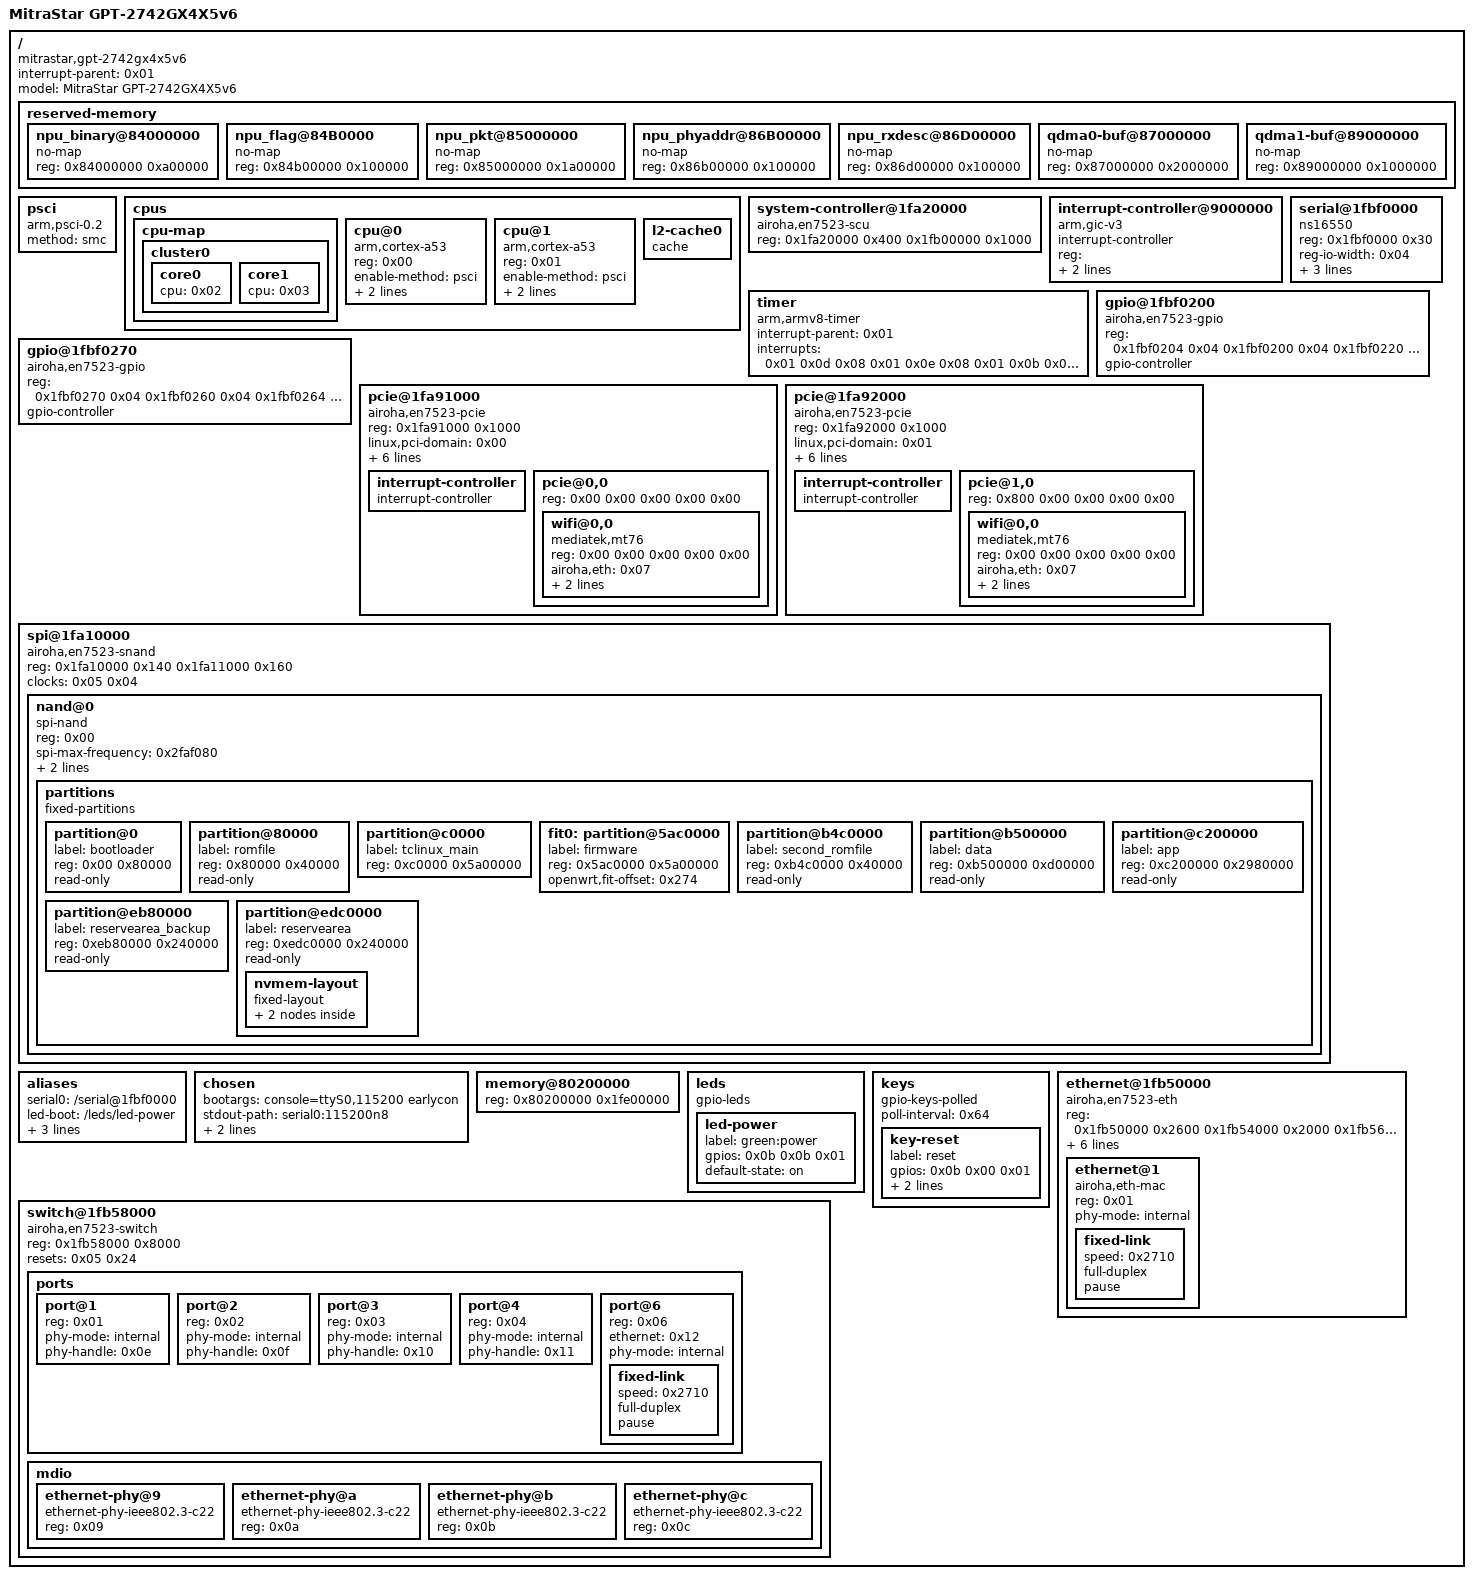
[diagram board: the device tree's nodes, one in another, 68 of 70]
/dts-v1/;

/memreserve/	0x0000000080000000 0x0000000000200000;
/ {
	interrupt-parent = <0x01>;
	#address-cells = <0x01>;
	#size-cells = <0x01>;
	model = "MitraStar GPT-2742GX4X5v6";
	compatible = "mitrastar,gpt-2742gx4x5v6\0airoha,en7523";

	reserved-memory {
		#address-cells = <0x01>;
		#size-cells = <0x01>;
		ranges;

		npu_binary@84000000 {
			no-map;
			reg = <0x84000000 0xa00000>;
		};

		npu_flag@84B0000 {
			no-map;
			reg = <0x84b00000 0x100000>;
		};

		npu_pkt@85000000 {
			no-map;
			reg = <0x85000000 0x1a00000>;
		};

		npu_phyaddr@86B00000 {
			no-map;
			reg = <0x86b00000 0x100000>;
		};

		npu_rxdesc@86D00000 {
			no-map;
			reg = <0x86d00000 0x100000>;
		};

		qdma0-buf@87000000 {
			no-map;
			reg = <0x87000000 0x2000000>;
			phandle = <0x0c>;
		};

		qdma1-buf@89000000 {
			no-map;
			reg = <0x89000000 0x1000000>;
			phandle = <0x0d>;
		};
	};

	psci {
		compatible = "arm,psci-0.2";
		method = "smc";
	};

	cpus {
		#address-cells = <0x01>;
		#size-cells = <0x00>;

		cpu-map {

			cluster0 {

				core0 {
					cpu = <0x02>;
				};

				core1 {
					cpu = <0x03>;
				};
			};
		};

		cpu@0 {
			device_type = "cpu";
			compatible = "arm,cortex-a53";
			reg = <0x00>;
			enable-method = "psci";
			clock-frequency = <0x4c4b400>;
			next-level-cache = <0x04>;
			phandle = <0x02>;
		};

		cpu@1 {
			device_type = "cpu";
			compatible = "arm,cortex-a53";
			reg = <0x01>;
			enable-method = "psci";
			clock-frequency = <0x4c4b400>;
			next-level-cache = <0x04>;
			phandle = <0x03>;
		};

		l2-cache0 {
			compatible = "cache";
			phandle = <0x04>;
		};
	};

	system-controller@1fa20000 {
		compatible = "airoha,en7523-scu";
		reg = <0x1fa20000 0x400 0x1fb00000 0x1000>;
		#clock-cells = <0x01>;
		#reset-cells = <0x01>;
		phandle = <0x05>;
	};

	interrupt-controller@9000000 {
		compatible = "arm,gic-v3";
		interrupt-controller;
		#interrupt-cells = <0x03>;
		#address-cells = <0x01>;
		#size-cells = <0x01>;
		reg = <0x9000000 0x20000 0x9080000 0x80000 0x9400000 0x2000 0x9500000 0x2000 0x9600000 0x20000>;
		interrupts = <0x01 0x09 0x08>;
		phandle = <0x01>;
	};

	timer {
		compatible = "arm,armv8-timer";
		interrupt-parent = <0x01>;
		interrupts = <0x01 0x0d 0x08 0x01 0x0e 0x08 0x01 0x0b 0x08 0x01 0x0a 0x08>;
	};

	serial@1fbf0000 {
		compatible = "ns16550";
		reg = <0x1fbf0000 0x30>;
		reg-io-width = <0x04>;
		reg-shift = <0x02>;
		interrupts = <0x00 0x12 0x04>;
		clock-frequency = <0x1c2000>;
		status = "okay";
	};

	gpio@1fbf0200 {
		compatible = "airoha,en7523-gpio";
		reg = <0x1fbf0204 0x04 0x1fbf0200 0x04 0x1fbf0220 0x04 0x1fbf0214 0x04>;
		gpio-controller;
		#gpio-cells = <0x02>;
		status = "okay";
		phandle = <0x0b>;
	};

	gpio@1fbf0270 {
		compatible = "airoha,en7523-gpio";
		reg = <0x1fbf0270 0x04 0x1fbf0260 0x04 0x1fbf0264 0x04 0x1fbf0278 0x04>;
		gpio-controller;
		#gpio-cells = <0x02>;
		status = "okay";
	};

	pcie@1fa91000 {
		compatible = "airoha,en7523-pcie\0mediatek,mt7622-pcie";
		device_type = "pci";
		reg = <0x1fa91000 0x1000>;
		reg-names = "port0";
		linux,pci-domain = <0x00>;
		#address-cells = <0x03>;
		#size-cells = <0x02>;
		interrupts = <0x00 0x27 0x04>;
		interrupt-names = "pcie_irq";
		clocks = <0x05 0x07>;
		clock-names = "sys_ck0";
		bus-range = <0x00 0xff>;
		ranges = <0x82000000 0x00 0x20000000 0x20000000 0x00 0x2000000>;
		status = "okay";
		#interrupt-cells = <0x01>;
		interrupt-map-mask = <0x00 0x00 0x00 0x07>;
		interrupt-map = <0x00 0x00 0x00 0x01 0x06 0x00 0x00 0x00 0x00 0x02 0x06 0x01 0x00 0x00 0x00 0x03 0x06 0x02 0x00 0x00 0x00 0x04 0x06 0x03>;

		interrupt-controller {
			interrupt-controller;
			#address-cells = <0x00>;
			#interrupt-cells = <0x01>;
			phandle = <0x06>;
		};

		pcie@0,0 {
			reg = <0x00 0x00 0x00 0x00 0x00>;
			#address-cells = <0x03>;
			#size-cells = <0x02>;

			wifi@0,0 {
				compatible = "mediatek,mt76";
				reg = <0x00 0x00 0x00 0x00 0x00>;
				airoha,eth = <0x07>;
				nvmem-cells = <0x08>;
				nvmem-cell-names = "eeprom";
			};
		};
	};

	pcie@1fa92000 {
		compatible = "airoha,en7523-pcie\0mediatek,mt7622-pcie";
		device_type = "pci";
		reg = <0x1fa92000 0x1000>;
		reg-names = "port1";
		linux,pci-domain = <0x01>;
		#address-cells = <0x03>;
		#size-cells = <0x02>;
		interrupts = <0x00 0x28 0x04>;
		interrupt-names = "pcie_irq";
		clocks = <0x05 0x07>;
		clock-names = "sys_ck1";
		bus-range = <0x00 0xff>;
		ranges = <0x82000000 0x00 0x22000000 0x22000000 0x00 0x2000000>;
		status = "okay";
		#interrupt-cells = <0x01>;
		interrupt-map-mask = <0x00 0x00 0x00 0x07>;
		interrupt-map = <0x00 0x00 0x00 0x01 0x09 0x00 0x00 0x00 0x00 0x02 0x09 0x01 0x00 0x00 0x00 0x03 0x09 0x02 0x00 0x00 0x00 0x04 0x09 0x03>;

		interrupt-controller {
			interrupt-controller;
			#address-cells = <0x00>;
			#interrupt-cells = <0x01>;
			phandle = <0x09>;
		};

		pcie@1,0 {
			reg = <0x800 0x00 0x00 0x00 0x00>;
			#address-cells = <0x03>;
			#size-cells = <0x02>;

			wifi@0,0 {
				compatible = "mediatek,mt76";
				reg = <0x00 0x00 0x00 0x00 0x00>;
				airoha,eth = <0x07>;
				nvmem-cells = <0x0a>;
				nvmem-cell-names = "eeprom";
			};
		};
	};

	spi@1fa10000 {
		compatible = "airoha,en7523-snand\0airoha,en7581-snand";
		reg = <0x1fa10000 0x140 0x1fa11000 0x160>;
		clocks = <0x05 0x04>;
		clock-names = "spi";
		#address-cells = <0x01>;
		#size-cells = <0x00>;

		nand@0 {
			compatible = "spi-nand";
			reg = <0x00>;
			spi-max-frequency = <0x2faf080>;
			spi-tx-bus-width = <0x01>;
			spi-rx-bus-width = <0x02>;
			status = "okay";

			partitions {
				compatible = "fixed-partitions";
				#address-cells = <0x01>;
				#size-cells = <0x01>;

				partition@0 {
					label = "bootloader";
					reg = <0x00 0x80000>;
					read-only;
				};

				partition@80000 {
					label = "romfile";
					reg = <0x80000 0x40000>;
					read-only;
				};

				partition@c0000 {
					label = "tclinux_main";
					reg = <0xc0000 0x5a00000>;
				};

				fit0: partition@5ac0000 {
					label = "firmware";
					reg = <0x5ac0000 0x5a00000>;
					openwrt,fit-offset = <0x274>;
				};

				partition@b4c0000 {
					label = "second_romfile";
					reg = <0xb4c0000 0x40000>;
					read-only;
				};

				partition@b500000 {
					label = "data";
					reg = <0xb500000 0xd00000>;
					read-only;
				};

				partition@c200000 {
					label = "app";
					reg = <0xc200000 0x2980000>;
					read-only;
				};

				partition@eb80000 {
					label = "reservearea_backup";
					reg = <0xeb80000 0x240000>;
					read-only;
				};

				partition@edc0000 {
					label = "reservearea";
					reg = <0xedc0000 0x240000>;
					read-only;

					nvmem-layout {
						compatible = "fixed-layout";
						#address-cells = <0x01>;
						#size-cells = <0x01>;

						eeprom@0 {
							reg = <0x00 0x1000>;
							phandle = <0x08>;
						};

						eeprom@20000 {
							reg = <0x20000 0x1000>;
							phandle = <0x0a>;
						};
					};
				};
			};
		};
	};

	aliases {
		serial0 = "/serial@1fbf0000";
		led-boot = "/leds/led-power";
		led-failsafe = "/leds/led-power";
		led-running = "/leds/led-power";
		led-upgrade = "/leds/led-power";
	};

	chosen {
		bootargs = "console=ttyS0,115200 earlycon";
		stdout-path = "serial0:115200n8";
		linux,usable-memory-range = <0x80200000 0x1fe00000>;
	};

	memory@80200000 {
		device_type = "memory";
		reg = <0x80200000 0x1fe00000>;
	};

	leds {
		compatible = "gpio-leds";

		led-power {
			label = "green:power";
			gpios = <0x0b 0x0b 0x01>;
			default-state = "on";
		};
	};

	keys {
		compatible = "gpio-keys-polled";
		poll-interval = <0x64>;

		key-reset {
			label = "reset";
			gpios = <0x0b 0x00 0x01>;
			linux,code = <0x198>;
			debounce-interval = <0x3c>;
		};
	};

	ethernet@1fb50000 {
		compatible = "airoha,en7523-eth";
		status = "okay";
		reg = <0x1fb50000 0x2600 0x1fb54000 0x2000 0x1fb56000 0x2000 0x1fbf9000 0x1000>;
		reg-names = "fe\0qdma0\0qdma1\0gdmp";
		resets = <0x05 0x22 0x05 0x14 0x05 0x15 0x05 0x0a 0x05 0x0b 0x05 0x0c 0x05 0x21>;
		reset-names = "fe\0pdma\0qdma\0hsi0-mac\0hsi1-mac\0hsi-mac\0gdmp";
		interrupts = <0x00 0x25 0x04 0x00 0x37 0x04 0x00 0x38 0x04 0x00 0x39 0x04 0x00 0x26 0x04 0x00 0x3a 0x04 0x00 0x3b 0x04 0x00 0x3c 0x04 0x00 0x31 0x04 0x00 0x40 0x04>;
		memory-region = <0x0c 0x0d>;
		memory-region-names = "qdma0-buf\0qdma1-buf";
		#address-cells = <0x01>;
		#size-cells = <0x00>;
		phandle = <0x07>;

		ethernet@1 {
			compatible = "airoha,eth-mac";
			reg = <0x01>;
			phy-mode = "internal";
			status = "okay";
			phandle = <0x12>;

			fixed-link {
				speed = <0x2710>;
				full-duplex;
				pause;
			};
		};
	};

	switch@1fb58000 {
		compatible = "airoha,en7523-switch";
		reg = <0x1fb58000 0x8000>;
		resets = <0x05 0x24>;
		status = "okay";
		#address-cells = <0x01>;
		#size-cells = <0x01>;

		ports {
			#address-cells = <0x01>;
			#size-cells = <0x00>;

			port@1 {
				reg = <0x01>;
				phy-mode = "internal";
				phy-handle = <0x0e>;
				status = "okay";
			};

			port@2 {
				reg = <0x02>;
				phy-mode = "internal";
				phy-handle = <0x0f>;
				status = "okay";
			};

			port@3 {
				reg = <0x03>;
				phy-mode = "internal";
				phy-handle = <0x10>;
				status = "okay";
			};

			port@4 {
				reg = <0x04>;
				phy-mode = "internal";
				phy-handle = <0x11>;
				status = "okay";
			};

			port@6 {
				reg = <0x06>;
				ethernet = <0x12>;
				phy-mode = "internal";

				fixed-link {
					speed = <0x2710>;
					full-duplex;
					pause;
				};
			};
		};

		mdio {
			#address-cells = <0x01>;
			#size-cells = <0x00>;

			ethernet-phy@9 {
				compatible = "ethernet-phy-ieee802.3-c22";
				reg = <0x09>;
				phandle = <0x0e>;
			};

			ethernet-phy@a {
				compatible = "ethernet-phy-ieee802.3-c22";
				reg = <0x0a>;
				phandle = <0x0f>;
			};

			ethernet-phy@b {
				compatible = "ethernet-phy-ieee802.3-c22";
				reg = <0x0b>;
				phandle = <0x10>;
			};

			ethernet-phy@c {
				compatible = "ethernet-phy-ieee802.3-c22";
				reg = <0x0c>;
				phandle = <0x11>;
			};
		};
	};
};
